VERSION ""

NS_ :

BS_ :

BU_ :

BO_ 3 FuelTankPressure: 8 Vector__XXX
  SG_ New_signal_2 : 7|8@0+ (1,0) [0|0] "" Vector__XXX

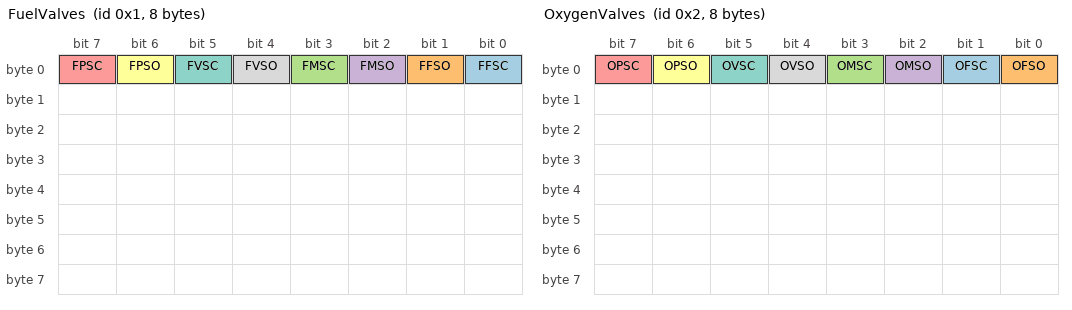
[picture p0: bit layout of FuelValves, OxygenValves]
BO_ 1 FuelValves: 8 Vector__XXX
  SG_ FFSC : 0|1@1+ (1,0) [0|0] "" Vector__XXX
  SG_ FFSO : 1|1@1+ (1,0) [0|0] "" Vector__XXX
  SG_ FMSC : 3|1@1+ (1,0) [0|0] "" Vector__XXX
  SG_ FMSO : 2|1@1+ (1,0) [0|0] "" Vector__XXX
  SG_ FPSC : 7|1@1+ (1,0) [0|0] "" Vector__XXX
  SG_ FPSO : 6|1@1+ (1,0) [0|0] "" Vector__XXX
  SG_ FVSC : 5|1@1+ (1,0) [0|0] "" Vector__XXX
  SG_ FVSO : 4|1@1+ (1,0) [0|0] "" Vector__XXX

BO_ 2 OxygenValves: 8 Vector__XXX
  SG_ OFSC : 1|1@1+ (1,0) [0|0] "" Vector__XXX
  SG_ OFSO : 0|1@1+ (1,0) [0|0] "" Vector__XXX
  SG_ OMSC : 3|1@1+ (1,0) [0|0] "" Vector__XXX
  SG_ OMSO : 2|1@1+ (1,0) [0|0] "" Vector__XXX
  SG_ OPSC : 7|1@1+ (1,0) [0|0] "" Vector__XXX
  SG_ OPSO : 6|1@1+ (1,0) [0|0] "" Vector__XXX
  SG_ OVSC : 5|1@1+ (1,0) [0|0] "" Vector__XXX
  SG_ OVSO : 4|1@1+ (1,0) [0|0] "" Vector__XXX

BA_DEF_ "DBName" STRING;
BA_DEF_ "BusType" STRING;
BA_DEF_ "ProtocolType" STRING;
BA_DEF_ BO_ "VFrameFormat" ENUM "StandardCAN","ExtendedCAN","reserved","J1939PG","reserved","reserved","reserved","reserved","reserved","reserved","reserved","reserved","reserved","reserved","StandardCAN_FD","ExtendedCAN_FD";
BA_DEF_ BO_ "GenMsgSendType" ENUM "Cyclic","Event","CyclicIfActive","SpontanWithDelay","CyclicAndSpontan","CyclicAndSpontanWithDelay";
BA_DEF_ BO_ "GenMsgCycleTime" INT 0 0;
BA_DEF_ BO_ "GenMsgDelayTime" INT 0 0;
BA_DEF_ BU_ "NmStationAddress" INT 0 255;
BA_DEF_DEF_ "DBName" "New_cluster_1";
BA_DEF_DEF_ "BusType" "CAN";
BA_DEF_DEF_ "ProtocolType" "J1939";
BA_DEF_DEF_ "VFrameFormat" "StandardCAN";
BA_DEF_DEF_ "GenMsgSendType" "Cyclic";
BA_DEF_DEF_ "GenMsgCycleTime" 0;
BA_DEF_DEF_ "GenMsgDelayTime" 0;
BA_DEF_DEF_ "NmStationAddress" 254;
BA_ "GenMsgCycleTime" BO_ 3 100;
BA_ "GenMsgSendType" BO_ 1 3;
BA_ "GenMsgDelayTime" BO_ 1 100;
BA_ "GenMsgSendType" BO_ 2 3;
BA_ "GenMsgDelayTime" BO_ 2 100;
